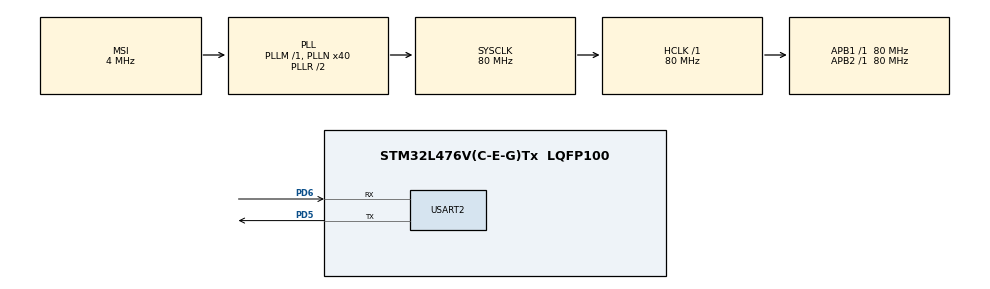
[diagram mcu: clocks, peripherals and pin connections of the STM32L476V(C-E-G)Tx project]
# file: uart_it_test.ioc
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Mcu.Family=STM32L4
Mcu.Name=STM32L476V(C-E-G)Tx
Mcu.Package=LQFP100
NVIC.PriorityGroup=NVIC_PRIORITYGROUP_4
NVIC.USART2_IRQn=true\:0\:0\:false\:false\:true\:true\:true
PD5.Mode=Asynchronous
PD5.Signal=USART2_TX
PD6.Mode=Asynchronous
PD6.Signal=USART2_RX
ProjectManager.HeapSize=0x200
ProjectManager.StackSize=0x400
ProjectManager.TargetToolchain=EWARM V8
RCC.AHBFreq_Value=80000000
RCC.APB1Freq_Value=80000000
RCC.APB1TimFreq_Value=80000000
RCC.APB2Freq_Value=80000000
RCC.APB2TimFreq_Value=80000000
RCC.CortexFreq_Value=80000000
RCC.HCLKFreq_Value=80000000
RCC.HSE_VALUE=8000000
RCC.HSI_VALUE=16000000
RCC.LSE_VALUE=32768
RCC.MSI_VALUE=4000000
RCC.PLLN=40
RCC.SYSCLKFreq_VALUE=80000000
RCC.SYSCLKSource=RCC_SYSCLKSOURCE_PLLCLK
RCC.VCOOutputFreq_Value=160000000
USART2.VirtualMode-Asynchronous=VM_ASYNC
board=custom

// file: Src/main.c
/* USER CODE BEGIN Header */
/**
  ******************************************************************************
  * @file           : main.c
  * @brief          : Main program body
  ******************************************************************************
  * @attention
  *
  * <h2><center>&copy; Copyright (c) 2019 STMicroelectronics.
  * All rights reserved.</center></h2>
  *
  * This software component is licensed by ST under BSD 3-Clause license,
  * the "License"; You may not use this file except in compliance with the
  * License. You may obtain a copy of the License at:
  *                        opensource.org/licenses/BSD-3-Clause
  *
  ******************************************************************************
  */
/* USER CODE END Header */

#include "main.h"

/* USER CODE BEGIN PD */
#define RX_BUFFER_SIZE        32

#define START_CMD         "start\n"
#define STOP_CMD          "stop\n"
#define LF                '\n'
#define CR                '\r'
#define CR_LF             "\r\n"
/* USER CODE END PD */

UART_HandleTypeDef huart2;

/* USER CODE BEGIN PV */
uint8_t aRxBuffer[RX_BUFFER_SIZE];
uint8_t byte;
volatile uint8_t index;
uint8_t size_of_last_data = 0;
/* USER CODE END PV */

void SystemClock_Config(void);
static void MX_GPIO_Init(void);
static void MX_USART2_UART_Init(void);

int main(void)
{

  /* MCU Configuration--------------------------------------------------------*/

  /* Reset of all peripherals, Initializes the Flash interface and the Systick. */
  HAL_Init();

  /* Configure the system clock */
  SystemClock_Config();

  /* Initialize all configured peripherals */
  MX_GPIO_Init();
  MX_USART2_UART_Init();
  /* USER CODE BEGIN 2 */
  HAL_UART_Receive_IT(&huart2, &byte, 1);
  /* USER CODE END 2 */

  /* Infinite loop */
  /* USER CODE BEGIN WHILE */
  while (1)
  {
    printf("Running in main\r\n");
    HAL_Delay(1000);
    /* USER CODE END WHILE */

  }
}

void SystemClock_Config(void)
{
  RCC_OscInitTypeDef RCC_OscInitStruct = {0};
  RCC_ClkInitTypeDef RCC_ClkInitStruct = {0};
  RCC_PeriphCLKInitTypeDef PeriphClkInit = {0};

  /** Initializes the CPU, AHB and APB busses clocks
  */
  RCC_OscInitStruct.OscillatorType = RCC_OSCILLATORTYPE_MSI;
  RCC_OscInitStruct.MSIState = RCC_MSI_ON;
  RCC_OscInitStruct.MSICalibrationValue = 0;
  RCC_OscInitStruct.MSIClockRange = RCC_MSIRANGE_6;
  RCC_OscInitStruct.PLL.PLLState = RCC_PLL_ON;
  RCC_OscInitStruct.PLL.PLLSource = RCC_PLLSOURCE_MSI;
  RCC_OscInitStruct.PLL.PLLM = 1;
  RCC_OscInitStruct.PLL.PLLN = 40;
  RCC_OscInitStruct.PLL.PLLP = RCC_PLLP_DIV7;
  RCC_OscInitStruct.PLL.PLLQ = RCC_PLLQ_DIV2;
  RCC_OscInitStruct.PLL.PLLR = RCC_PLLR_DIV2;
  if (HAL_RCC_OscConfig(&RCC_OscInitStruct) != HAL_OK)
  {
    Error_Handler();
  }
  /** Initializes the CPU, AHB and APB busses clocks
  */
  RCC_ClkInitStruct.ClockType = RCC_CLOCKTYPE_HCLK|RCC_CLOCKTYPE_SYSCLK
                              |RCC_CLOCKTYPE_PCLK1|RCC_CLOCKTYPE_PCLK2;
  RCC_ClkInitStruct.SYSCLKSource = RCC_SYSCLKSOURCE_PLLCLK;
  RCC_ClkInitStruct.AHBCLKDivider = RCC_SYSCLK_DIV1;
  RCC_ClkInitStruct.APB1CLKDivider = RCC_HCLK_DIV1;
  RCC_ClkInitStruct.APB2CLKDivider = RCC_HCLK_DIV1;

  if (HAL_RCC_ClockConfig(&RCC_ClkInitStruct, FLASH_LATENCY_4) != HAL_OK)
  {
    Error_Handler();
  }
  PeriphClkInit.PeriphClockSelection = RCC_PERIPHCLK_USART2;
  PeriphClkInit.Usart2ClockSelection = RCC_USART2CLKSOURCE_PCLK1;
  if (HAL_RCCEx_PeriphCLKConfig(&PeriphClkInit) != HAL_OK)
  {
    Error_Handler();
  }
  /** Configure the main internal regulator output voltage
  */
  if (HAL_PWREx_ControlVoltageScaling(PWR_REGULATOR_VOLTAGE_SCALE1) != HAL_OK)
  {
    Error_Handler();
  }
}

static void MX_USART2_UART_Init(void)
{

  huart2.Instance = USART2;
  huart2.Init.BaudRate = 115200;
  huart2.Init.WordLength = UART_WORDLENGTH_8B;
  huart2.Init.StopBits = UART_STOPBITS_1;
  huart2.Init.Parity = UART_PARITY_NONE;
  huart2.Init.Mode = UART_MODE_TX_RX;
  huart2.Init.HwFlowCtl = UART_HWCONTROL_NONE;
  huart2.Init.OverSampling = UART_OVERSAMPLING_16;
  huart2.Init.OneBitSampling = UART_ONE_BIT_SAMPLE_DISABLE;
  huart2.AdvancedInit.AdvFeatureInit = UART_ADVFEATURE_NO_INIT;
  if (HAL_UART_Init(&huart2) != HAL_OK)
  {
    Error_Handler();
  }

}

static void MX_GPIO_Init(void)
{

  /* GPIO Ports Clock Enable */
  __HAL_RCC_GPIOD_CLK_ENABLE();

}

/* USER CODE BEGIN 4 */
void HAL_UART_RxCpltCallback(UART_HandleTypeDef *huart)
{
  // printf("Rx Callback\r\n");
  if (huart->Instance == USART2)
  {
    aRxBuffer[index] = byte;
    if (byte == LF)
    {
      printf("Should Echo Here\n");
      HAL_UART_Transmit(&huart2, aRxBuffer, index, 100);
      /*
        if (strstr((char *) aRxBuffer, "start\r\n") != NULL)
        {
          printf("Starting Timer\n");
        }
        else if (strstr((char *) aRxBuffer, "stop\r\n") != NULL)
        {
          printf("Stopping Timer\n");
        }
      */
      memset(aRxBuffer, 0, RX_BUFFER_SIZE);
      index = 0;
    }
    index++;
    HAL_UART_Receive_IT(&huart2, &byte, 1);
  }
}
/* USER CODE END 4 */

void Error_Handler(void)
{
  /* USER CODE BEGIN Error_Handler_Debug */
  /* User can add his own implementation to report the HAL error return state */
  printf("Error Handler\r\n");
  while (1);
  /* USER CODE END Error_Handler_Debug */
}

/************************ (C) COPYRIGHT STMicroelectronics *****END OF FILE****/
